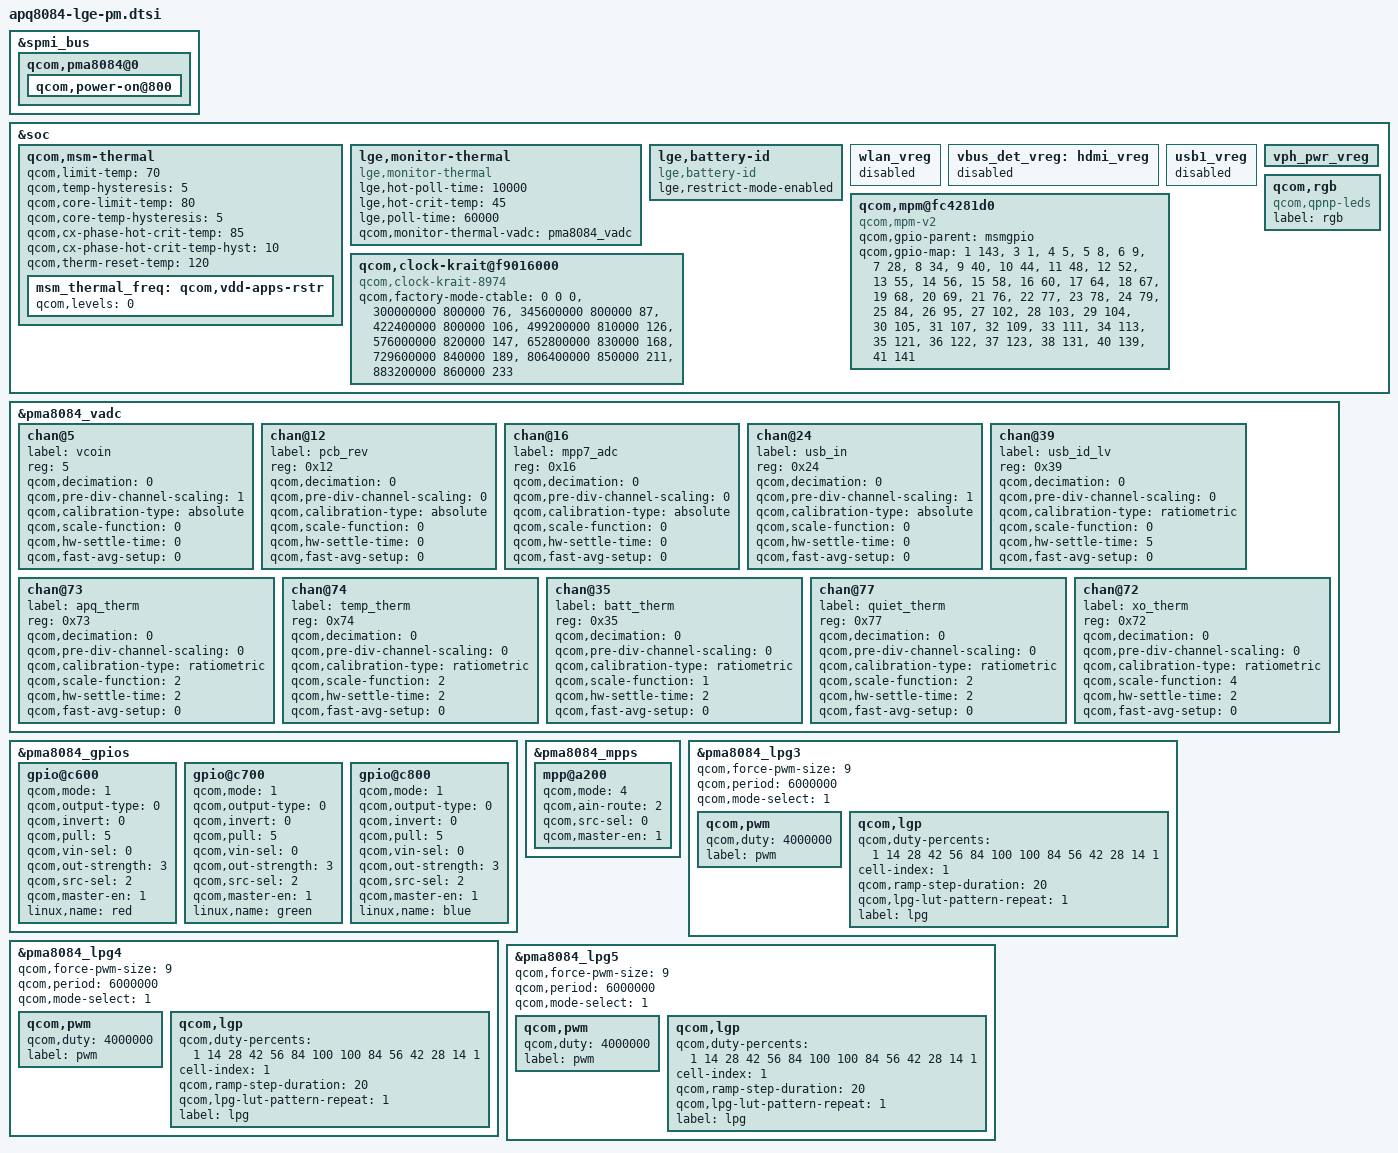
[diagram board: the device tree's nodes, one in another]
/* Copyright (c) 2012, Code Aurora Forum. All rights reserved.
 *
 * This program is free software; you can redistribute it and/or modify
 * it under the terms of the GNU General Public License version 2 and
 * only version 2 as published by the Free Software Foundation.
 *
 * This program is distributed in the hope that it will be useful,
 * but WITHOUT ANY WARRANTY; without even the implied warranty of
 * MERCHANTABILITY or FITNESS FOR A PARTICULAR PURPOSE.  See the
 * GNU General Public License for more details.
 */

&spmi_bus {
	qcom,pma8084@0 {
		qcom,power-on@800 {
			/delete-node/ qcom,pon_2;
			/delete-node/ qcom,pon_3;
		};
	};
};

&soc {
	qcom,msm-thermal {
		qcom,limit-temp = <70>;
		qcom,temp-hysteresis = <5>;
		qcom,core-limit-temp = <80>;
		qcom,core-temp-hysteresis = <5>;
		qcom,cx-phase-hot-crit-temp = <85>;
		qcom,cx-phase-hot-crit-temp-hyst = <10>;
		qcom,therm-reset-temp = <120>;

		msm_thermal_freq: qcom,vdd-apps-rstr{
			qcom,levels = <0>;
		};
	};

	lge,monitor-thermal {
		compatible = "lge,monitor-thermal";
		lge,hot-poll-time = <10000>;
		lge,hot-crit-temp = <45>;
		lge,poll-time = <60000>;
		qcom,monitor-thermal-vadc = <&pma8084_vadc>;
	};

	lge,battery-id {
		compatible = "lge,battery-id";
		lge,restrict-mode-enabled;
	};

	wlan_vreg {
		status = "disable";
	};

	vbus_det_vreg: hdmi_vreg{
		status = "disable";
	};

	usb1_vreg {
		status = "disable";
	};

	vph_pwr_vreg {
		status = "ok";
	};

	qcom,mpm@fc4281d0 {
		compatible = "qcom,mpm-v2";

		qcom,gpio-parent = <&msmgpio>;
		qcom,gpio-map = <1 143>,
			<3 1>,
			<4 5>,
			<5 8>,
			<6 9>,
			<7 28>,
			<8 34>,
			<9 40>,
			<10 44>,
			<11 48>,
			<12 52>,
			<13 55>,
			<14 56>,
			<15 58>,
			<16 60>,
			<17 64>,
			<18 67>,
			<19 68>,
			<20 69>,
			<21 76>,
			<22 77>,
			<23 78>,
			<24 79>,
			<25 84>,
			<26 95>,
			<27 102>,
			<28 103>,
			<29 104>,
			<30 105>,
			<31 107>,
			<32 109>,
			<33 111>,
			<34 113>,
			<35 121>,
			<36 122>,
			<37 123>,
			<38 131>,
			<40 139>,
			<41 141>;
	};

	qcom,clock-krait@f9016000 {
		compatible = "qcom,clock-krait-8974";
		qcom,factory-mode-ctable =
			<          0       0    0 >,
			<  300000000  800000   76 >,
			<  345600000  800000   87 >,
			<  422400000  800000  106 >,
			<  499200000  810000  126 >,
			<  576000000  820000  147 >,
			<  652800000  830000  168 >,
			<  729600000  840000  189 >,
			<  806400000  850000  211 >,
			<  883200000  860000  233 >;
	};
};

&pma8084_vadc {

	chan@5 {
		label = "vcoin";
		reg = <5>;
		qcom,decimation = <0>;
		qcom,pre-div-channel-scaling = <1>;
		qcom,calibration-type = "absolute";
		qcom,scale-function = <0>;
		qcom,hw-settle-time = <0>;
		qcom,fast-avg-setup = <0>;
	};

	chan@12 {
		label = "pcb_rev";
		reg = <0x12>;
		qcom,decimation = <0>;
		qcom,pre-div-channel-scaling = <0>;
		qcom,calibration-type = "absolute";
		qcom,scale-function = <0>;
		qcom,hw-settle-time = <0>;
		qcom,fast-avg-setup = <0>;
	};

	chan@16 {
		label="mpp7_adc";
		reg = <0x16>;
		qcom,decimation = <0>;
		qcom,pre-div-channel-scaling = <0>;
		qcom,calibration-type = "absolute";
		qcom,scale-function = <0>;
		qcom,hw-settle-time = <0>;
		qcom,fast-avg-setup = <0>;
	};

	chan@24 {
		label="usb_in";
		reg = <0x24>;
		qcom,decimation = <0>;
		qcom,pre-div-channel-scaling = <1>;
		qcom,calibration-type = "absolute";
		qcom,scale-function = <0>;
		qcom,hw-settle-time = <0>;
		qcom,fast-avg-setup = <0>;
	};

	chan@39 {
		label = "usb_id_lv";
		reg = <0x39>;
		qcom,decimation = <0>;
		qcom,pre-div-channel-scaling = <0>;
		qcom,calibration-type = "ratiometric";
		qcom,scale-function = <0>;
		qcom,hw-settle-time = <5>;
		qcom,fast-avg-setup = <0>;
	};

	chan@73 {
		label = "apq_therm";
		reg = <0x73>;
		qcom,decimation = <0>;
		qcom,pre-div-channel-scaling = <0>;
		qcom,calibration-type = "ratiometric";
		qcom,scale-function = <2>;
		qcom,hw-settle-time = <2>;
		qcom,fast-avg-setup = <0>;
	};

	chan@74 {
		label = "temp_therm";
		reg = <0x74>;
		qcom,decimation = <0>;
		qcom,pre-div-channel-scaling = <0>;
		qcom,calibration-type = "ratiometric";
		qcom,scale-function = <2>;
		qcom,hw-settle-time = <2>;
		qcom,fast-avg-setup = <0>;
	};

	chan@35 {
		label = "batt_therm";
		reg = <0x35>;
		qcom,decimation = <0>;
		qcom,pre-div-channel-scaling = <0>;
		qcom,calibration-type = "ratiometric";
		qcom,scale-function = <1>;
		qcom,hw-settle-time = <2>;
		qcom,fast-avg-setup = <0>;
	};

	chan@77 {
		label = "quiet_therm";
		reg = <0x77>;
		qcom,decimation = <0>;
		qcom,pre-div-channel-scaling = <0>;
		qcom,calibration-type = "ratiometric";
		qcom,scale-function = <2>;
		qcom,hw-settle-time = <2>;
		qcom,fast-avg-setup = <0>;
	};

	chan@72 {
		label = "xo_therm";
		reg = <0x72>;
		qcom,decimation = <0>;
		qcom,pre-div-channel-scaling = <0>;
		qcom,calibration-type = "ratiometric";
		qcom,scale-function = <4>;
		qcom,hw-settle-time = <2>;
		qcom,fast-avg-setup = <0>;
	};

};

&pma8084_gpios {
	gpio@c600 { /* GPIO 7 */
		qcom,mode = <1>;		/* QPNP_PIN_MODE_DIG_OUT */
		qcom,output-type = <0>;		/* QPNP_PIN_OUT_BUF_CMOS */
		qcom,invert = <0>;		/* QPNP_PIN_INVERT_DISABLE */
		qcom,pull = <5>;                /* QPNP_PIN_PULL_NO */
		qcom,vin-sel = <0>;
		qcom,out-strength = <3>;        /* QPNP_PIN_OUT_STRENTH_HIGH */
		qcom,src-sel = <2>;
		qcom,master-en = <1>;
		linux,name = "red";
	};

	gpio@c700 { /* GPIO 8 */
		qcom,mode = <1>;		/* QPNP_PIN_MODE_DIG_OUT */
		qcom,output-type = <0>;		/* QPNP_PIN_OUT_BUF_CMOS */
		qcom,invert = <0>;		/* QPNP_PIN_INVERT_DISABLE */
		qcom,pull = <5>;                /* QPNP_PIN_PULL_NO */
		qcom,vin-sel = <0>;
		qcom,out-strength = <3>;        /* QPNP_PIN_OUT_STRENTH_HIGH */
		qcom,src-sel = <2>;
		qcom,master-en = <1>;
		linux,name = "green";
	};

	gpio@c800 { /* GPIO 9 */
		qcom,mode = <1>;		/* QPNP_PIN_MODE_DIG_OUT */
		qcom,output-type = <0>;		/* QPNP_PIN_OUT_BUF_CMOS */
		qcom,invert = <0>;		/* QPNP_PIN_INVERT_DISABLE */
		qcom,pull = <5>;                /* QPNP_PIN_PULL_NO */
		qcom,vin-sel = <0>;
		qcom,out-strength = <3>;        /* QPNP_PIN_OUT_STRENTH_HIGH */
		qcom,src-sel = <2>;
		qcom,master-en = <1>;
		linux,name = "blue";
	};
};

&pma8084_mpps {

	mpp@a200 { /* MPP 3 */
		qcom,mode = <4>;
		qcom,ain-route = <2>;
		qcom,src-sel = <0>;
		qcom,master-en = <1>;
	};
};

&pma8084_lpg3 {
	qcom,force-pwm-size = <9>;
	qcom,period = <6000000>;
	qcom,mode-select = <1>;
	status = "okay";
	qcom,pwm {
		qcom,duty = <4000000>;
		label = "pwm";
	};
	qcom,lgp {
		qcom,duty-percents = <1 14 28 42 56 84 100 100 84 56 42 28 14 1>;
		cell-index = <1>;
		qcom,ramp-step-duration = <20>;
		qcom,lpg-lut-pattern-repeat = <1>;
		label = "lpg";
	};
};

&pma8084_lpg4 {
	qcom,force-pwm-size = <9>;
	qcom,period = <6000000>;
	qcom,mode-select = <1>;
	status = "okay";
	qcom,pwm {
		qcom,duty = <4000000>;
		label = "pwm";
	};
	qcom,lgp {
		qcom,duty-percents = <1 14 28 42 56 84 100 100 84 56 42 28 14 1>;
		cell-index = <1>;
		qcom,ramp-step-duration = <20>;
		qcom,lpg-lut-pattern-repeat = <1>;
		label = "lpg";
	};
};

&pma8084_lpg5 {
	qcom,force-pwm-size = <9>;
	qcom,period = <6000000>;
	qcom,mode-select = <1>;
	status = "okay";
	qcom,pwm {
		qcom,duty = <4000000>;
		label = "pwm";
	};
	qcom,lgp {
		qcom,duty-percents = <1 14 28 42 56 84 100 100 84 56 42 28 14 1>;
		cell-index = <1>;
		qcom,ramp-step-duration = <20>;
		qcom,lpg-lut-pattern-repeat = <1>;
		label = "lpg";
	};
};

&soc {
	qcom,rgb {
		label = "rgb";
		compatible = "qcom,qpnp-leds";
		status = "ok";
	};
};
